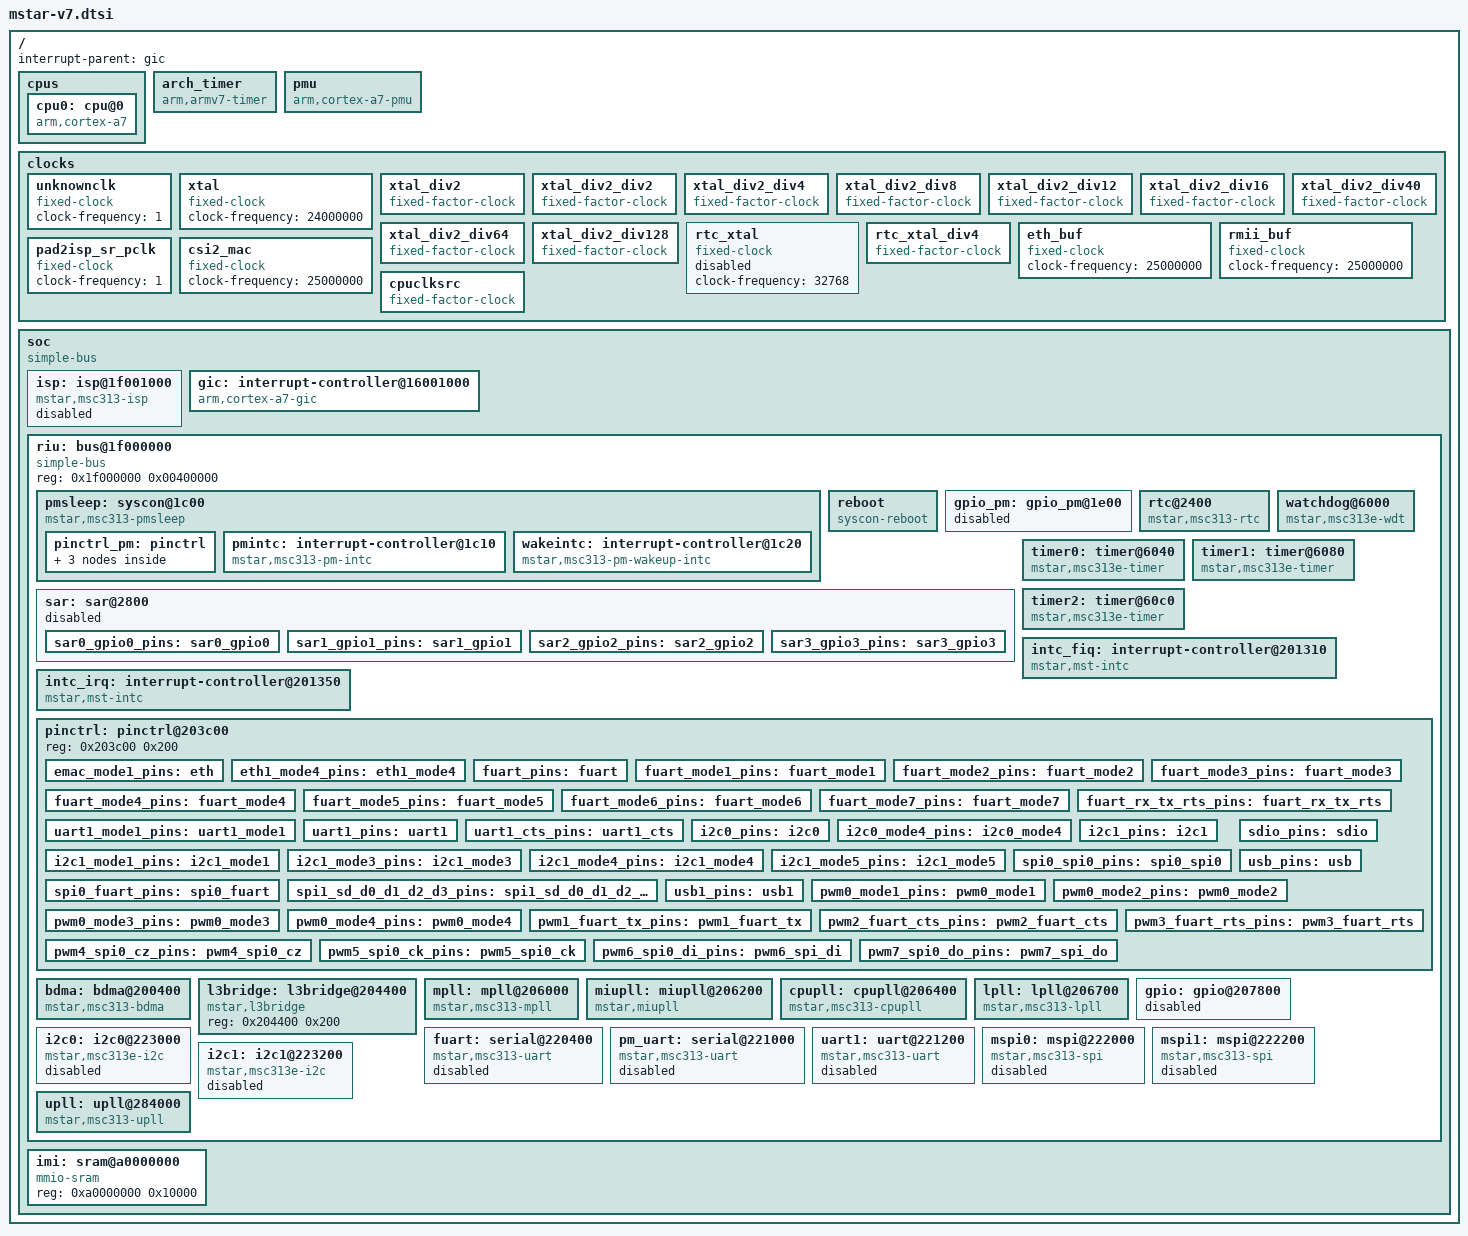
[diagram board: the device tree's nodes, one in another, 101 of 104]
// SPDX-License-Identifier: GPL-2.0-or-later
/*
 * Copyright (c) 2020 thingy.jp.
 * Author: Daniel Palmer <daniel@thingy.jp>
 */

#include <dt-bindings/interrupt-controller/irq.h>
#include <dt-bindings/interrupt-controller/arm-gic.h>
#include <dt-bindings/clock/mstar-msc313-mpll.h>

/ {
	#address-cells = <1>;
	#size-cells = <1>;
	interrupt-parent = <&gic>;

	cpus: cpus {
		#address-cells = <1>;
		#size-cells = <0>;

		cpu0: cpu@0 {
			device_type = "cpu";
			compatible = "arm,cortex-a7";
			reg = <0x0>;
			clocks = <&cpupll>;
			clock-names = "cpuclk";
		};
	};

	arch_timer {
		compatible = "arm,armv7-timer";
		interrupts = <GIC_PPI 13 (GIC_CPU_MASK_SIMPLE(2)
				| IRQ_TYPE_LEVEL_LOW)>,
			     <GIC_PPI 14 (GIC_CPU_MASK_SIMPLE(2)
				| IRQ_TYPE_LEVEL_LOW)>,
			     <GIC_PPI 11 (GIC_CPU_MASK_SIMPLE(2)
				| IRQ_TYPE_LEVEL_LOW)>,
			     <GIC_PPI 10 (GIC_CPU_MASK_SIMPLE(2)
				| IRQ_TYPE_LEVEL_LOW)>;
		/*
		 * we shouldn't need this but the vendor
		 * u-boot is broken
		 */
		clock-frequency = <6000000>;
		arm,cpu-registers-not-fw-configured;
	};

	pmu: pmu {
		compatible = "arm,cortex-a7-pmu";
		interrupts = <GIC_SPI 10 IRQ_TYPE_LEVEL_HIGH>;
/*		interrupts = <GIC_SPI 10 IRQ_TYPE_LEVEL_HIGH>,
			     <GIC_SPI 16 IRQ_TYPE_LEVEL_HIGH>,
			     <GIC_SPI 22 IRQ_TYPE_LEVEL_HIGH>,
			     <GIC_SPI 28 IRQ_TYPE_LEVEL_HIGH>; */
		interrupt-affinity = <&cpu0>;
	};

	clocks: clocks {
		unknownclk: unknownclk {
			#clock-cells = <0>;
			compatible = "fixed-clock";
			clock-frequency = <1>;
		};

		/*
		 * For the msc313e there is only a 24mhz clock input so everything else must come
		 * from this base clock unless there are some on-die oscillators that aren't mentioned
		 * anywhere.
		 */
		xtal: xtal {
			#clock-cells = <0>;
			compatible = "fixed-clock";
			clock-frequency = <24000000>;
		};

		xtal_div2: xtal_div2 {
			#clock-cells = <0>;
			compatible = "fixed-factor-clock";
			clocks = <&xtal>;
			clock-div = <2>;
			clock-mult = <1>;
		};
		
		xtal_div2_div2: xtal_div2_div2 {
			compatible = "fixed-factor-clock";
			#clock-cells = <0>;
			clocks = <&xtal_div2>;
			clock-div = <2>;
			clock-mult = <1>;
		};

		xtal_div2_div4: xtal_div2_div4 {
			compatible = "fixed-factor-clock";
			#clock-cells = <0>;
			clocks = <&xtal_div2>;
			clock-div = <4>;
			clock-mult = <1>;
		};

		xtal_div2_div8: xtal_div2_div8 {
			compatible = "fixed-factor-clock";
			#clock-cells = <0>;
			clocks = <&xtal_div2>;
			clock-div = <8>;
			clock-mult = <1>;
		};

		xtal_div2_div12: xtal_div2_div12 {
			compatible = "fixed-factor-clock";
			#clock-cells = <0>;
			clocks = <&xtal_div2>;
			clock-div = <12>;
			clock-mult = <1>;
		};

		xtal_div2_div16: xtal_div2_div16 {
			compatible = "fixed-factor-clock";
			#clock-cells = <0>;
			clocks = <&xtal_div2>;
			clock-div = <16>;
			clock-mult = <1>;
		};

		xtal_div2_div40: xtal_div2_div40 {
			compatible = "fixed-factor-clock";
			#clock-cells = <0>;
			clocks = <&xtal_div2>;
			clock-div = <40>;
			clock-mult = <1>;
		};

		xtal_div2_div64: xtal_div2_div64 {
			compatible = "fixed-factor-clock";
			#clock-cells = <0>;
			clocks = <&xtal_div2>;
			clock-div = <64>;
			clock-mult = <1>;
		};

		xtal_div2_div128: xtal_div2_div128 {
			compatible = "fixed-factor-clock";
			#clock-cells = <0>;
			clocks = <&xtal_div2>;
			clock-div = <128>;
			clock-mult = <1>;
		};

		rtc_xtal: rtc_xtal {
			#clock-cells = <0>;
			compatible = "fixed-clock";
			clock-frequency = <32768>;
			status = "disabled";
		};

		rtc_xtal_div4: rtc_xtal_div4 {
			compatible = "fixed-factor-clock";
			#clock-cells = <0>;
			clocks = <&rtc_xtal>;
			clock-div = <4>;
			clock-mult = <1>;
		};

		eth_buf: eth_buf {
			#clock-cells = <0>;
			compatible = "fixed-clock";
			clock-frequency = <25000000>;
		};

		rmii_buf: rmii_buf {
			#clock-cells = <0>;
			compatible = "fixed-clock";
			clock-frequency = <25000000>;
		};
		
		pad2isp_sr_pclk: pad2isp_sr_pclk {
			#clock-cells = <0>;
			compatible = "fixed-clock";
			clock-frequency = <1>;
		};
	
		csi2_mac: csi2_mac {
			#clock-cells = <0>;
			compatible = "fixed-clock";
			clock-frequency = <25000000>;
		};

		/*
		 * this is a dummy for now, there must be a switch for the
		 * cpu clk to move between the mpll and the xtal, the spi nor
		 * controller also uses this clock and it works before the
		 * mpll is enabled
		 */
		cpuclksrc: cpuclksrc {
			compatible = "fixed-factor-clock";
			#clock-cells = <0>;
			clocks = <&mpll 1>;
			clock-div = <1>;
			clock-mult = <1>;
		};
	};

	soc: soc {
		compatible = "simple-bus";
		#address-cells = <1>;
		#size-cells = <1>;
		ranges = <0x14000000 0x14000000 0x1000000>,
			 <0x16001000 0x16001000 0x00007000>,
			 <0x1f000000 0x1f000000 0x00400000>,
			 <0xa0000000 0xa0000000 0x20000>;

		isp: isp@1f001000 {
			#address-cells = <1>;
			#size-cells = <0>;
			compatible = "mstar,msc313-isp";
			reg = <0x1f001000 0x400>,
			      <0x1f002c00 0x200>,
			      <0x1f002e00 0x200>,
			      <0x14000000 0x1000000>;
			clock-names = "pm_spi", "cpuclk", "spi";
			clocks = <&pm_muxes MSC313_PM_MUXES_SPI_PM>,
				 <&cpuclksrc>,
				 <&clkgen MSC313_CLKGEN_DEGLITCHES MSC313_CLKGEN_SPI 0>;
			interrupts-extended = <&intc_irq GIC_SPI 5 IRQ_TYPE_LEVEL_HIGH>;
			dmas = <&bdma 0>;
			dma-names = "qspi";
			pinctrl-names = "default";
			pinctrl-0 = <&pm_spi_pins>;
			status = "disabled";
			interconnects = <&miu 0>;
			interconnect-names = "dma-mem";
		};

		gic: interrupt-controller@16001000 {
			compatible = "arm,cortex-a7-gic";
			reg = <0x16001000 0x1000>,
			      <0x16002000 0x2000>,
			      <0x16004000 0x2000>,
			      <0x16006000 0x2000>;
			#interrupt-cells = <3>;
			interrupt-controller;
			interrupts = <GIC_PPI 9 (GIC_CPU_MASK_SIMPLE(2)
					| IRQ_TYPE_LEVEL_LOW)>;
		};

		riu: bus@1f000000 {
			compatible = "simple-bus";
			reg = <0x1f000000 0x00400000>;
			#address-cells = <1>;
			#size-cells = <1>;
			ranges = <0x0 0x1f000000 0x00400000>;

			pmsleep: syscon@1c00 {
				/* msc313e notes
				 *
				 * 1f001c24 -- bit 11 disables pm uart rx
				 * -- bit 15 is set when going into deep sleep
				 *
				 *
				 * 0x1f001cec -- return address after resume
				 * 0x1f001cf0
				 * 0x1f001cf4 -- clk for timers?
				 * 0x1f001cc0 -- ??
				 * 0x1f001cc8  -- set to 9fe8 before deep sleep
				 * 0x1f001ccc  -- set to 9fe8 before deep sleep
				 * 0x1f001cdc  -- set to 0xa5 before deep sleep
				 */
				compatible = "mstar,msc313-pmsleep", "syscon", "simple-mfd";
				reg = <0x1c00 0x100>;
				use-raw-spinlock;

				pinctrl_pm: pinctrl {
					pm_uart_pins: pm_uart {
						function = "pm_uart";
						groups = "pm_uart";
					};
					pm_spi_pins: pm_spi {
						function = "pm_spi";
						groups = "pm_spi";
					};
					pm_irin_pins: pm_irin {
						function = "pm_irin";
						groups = "pm_irin";
					};
				};

				pmintc: interrupt-controller@1c10 {
					compatible = "mstar,msc313-pm-intc";
					interrupt-parent = <&intc_irq>;
					interrupts = <GIC_SPI 2 IRQ_TYPE_LEVEL_HIGH>;
					interrupt-controller;
					#interrupt-cells = <1>;
				};

				wakeintc: interrupt-controller@1c20 {
					compatible = "mstar,msc313-pm-wakeup-intc";
					interrupt-parent = <&intc_irq>;
					interrupts = <GIC_SPI 2 IRQ_TYPE_LEVEL_HIGH>;
					interrupt-controller;
					#interrupt-cells = <2>;
					mstar,pmsleep = <&pmsleep>;
				};
			};

			reboot {
				compatible = "syscon-reboot";
				regmap = <&pmsleep>;
				offset = <0xb8>;
				mask = <0x79>;
			};

			gpio_pm: gpio_pm@1e00 {
				reg = <0x1e00 0x200>;
				#gpio-cells = <2>;
				gpio-controller;
				interrupt-controller;
				#interrupt-cells = <3>;
				interrupt-parent = <&pmintc>;
				status = "disabled";
			};

			rtc@2400 {
				compatible = "mstar,msc313-rtc";
				reg = <0x2400 0x40>;
				clocks = <&xtal_div2>;
				interrupts-extended = <&intc_irq GIC_SPI 44 IRQ_TYPE_LEVEL_HIGH>;
			};

			sar: sar@2800 {
				#gpio-cells = <2>;
				#io-channel-cells = <1>;
				reg = <0x2800 0x200>;
				interrupts-extended = <&intc_irq GIC_SPI 45 IRQ_TYPE_LEVEL_HIGH>,
						      <&wakeintc 1 IRQ_TYPE_LEVEL_HIGH>,
						      <&wakeintc 6 IRQ_TYPE_LEVEL_HIGH>,
						      <&intc_fiq GIC_SPI 24 IRQ_TYPE_LEVEL_HIGH>,
						      <&intc_fiq GIC_SPI 25 IRQ_TYPE_LEVEL_HIGH>,
						      <&intc_fiq GIC_SPI 26 IRQ_TYPE_LEVEL_HIGH>,
						      <&intc_fiq GIC_SPI 27 IRQ_TYPE_LEVEL_HIGH>;
				interrupt-names = "sar",
						  "wakeup",
						  "wakeup_gpio",
						  "sar_gpio0",
						  "sar_gpio1",
						  "sar_gpio2",
						  "sar_gpio3";
				clock-names = "sar_clk";
				clocks = <&pm_muxes MSC313_PM_MUXES_SAR>;
				mstar,pmsleep = <&pmsleep>;
				wakeup-source;
				status = "disabled";
				sar0_gpio0_pins: sar0_gpio0 {
					function = "sar0";
					groups = "sar_gpio0";
				};
				sar1_gpio1_pins: sar1_gpio1 {
					function = "sar1";
					groups = "sar_gpio1";
				};
				sar2_gpio2_pins: sar2_gpio2 {
					function = "sar2";
					groups = "sar_gpio2";
				};
				sar3_gpio3_pins: sar3_gpio3 {
					function = "sar3";
					groups = "sar_gpio3";
				};
			};

			watchdog@6000 {
				compatible = "mstar,msc313e-wdt";
				reg = <0x6000 0x1f>;
				clocks = <&xtal_div2>;
			};

			timer0: timer@6040 {
				compatible = "mstar,msc313e-timer";
				reg = <0x6040 0x40>;
				clocks = <&xtal_div2>;
				interrupts-extended = <&intc_fiq GIC_SPI 0 IRQ_TYPE_LEVEL_HIGH>;
			};

			timer1: timer@6080 {
				compatible = "mstar,msc313e-timer";
				reg = <0x6080 0x40>;
				clocks = <&xtal_div2>;
				interrupts-extended = <&intc_fiq GIC_SPI 1 IRQ_TYPE_LEVEL_HIGH>;
			};

			timer2: timer@60c0 {
				compatible = "mstar,msc313e-timer";
				reg = <0x60c0 0x40>;
				clocks = <&xtal_div2>;
				interrupts-extended = <&intc_fiq GIC_SPI 12 IRQ_TYPE_LEVEL_HIGH>;
			};

			intc_fiq: interrupt-controller@201310 {
				compatible = "mstar,mst-intc";
				reg = <0x201310 0x40>;
				#interrupt-cells = <3>;
				interrupt-controller;
				interrupt-parent = <&gic>;
				mstar,irqs-map-range = <96 127>;
			};

			intc_irq: interrupt-controller@201350 {
				compatible = "mstar,mst-intc";
				reg = <0x201350 0x40>;
				#interrupt-cells = <3>;
				interrupt-controller;
				interrupt-parent = <&gic>;
				mstar,irqs-map-range = <32 95>;
				mstar,intc-no-eoi;
			};

			pinctrl: pinctrl@203c00 {
				reg = <0x203c00 0x200>;
				emac_mode1_pins: eth {
					function = "eth";
					groups = "eth_mode1";
				};
				eth1_mode4_pins: eth1_mode4 {
					function = "eth1";
					groups = "eth1_mode4";
				};
				fuart_pins: fuart {
					function = "fuart";
					groups = "fuart";
				};
				fuart_mode1_pins: fuart_mode1 {
					function = "fuart";
					groups = "fuart_mode1";
				};
				fuart_mode2_pins: fuart_mode2 {
					function = "fuart";
					groups = "fuart_mode2";
				};
				fuart_mode3_pins: fuart_mode3 {
					function = "fuart";
					groups = "fuart_mode3";
				};
				fuart_mode4_pins: fuart_mode4 {
					function = "fuart";
					groups = "fuart_mode4";
				};
				fuart_mode5_pins: fuart_mode5 {
					function = "fuart";
					groups = "fuart_mode5";
				};
				fuart_mode6_pins: fuart_mode6 {
					function = "fuart";
					groups = "fuart_mode6";
				};
				fuart_mode7_pins: fuart_mode7 {
					function = "fuart";
					groups = "fuart_mode7";
				};
				fuart_rx_tx_rts_pins: fuart_rx_tx_rts {
					function = "fuart";
					groups = "fuart_rx_tx_rts";
				};
				uart1_mode1_pins: uart1_mode1 {
					function = "uart1";
					groups = "uart1_mode1";
				};
				uart1_pins: uart1 {
					function = "uart1";
					groups = "fuart_cts_rts";
				};
				uart1_cts_pins: uart1_cts {
					function = "uart1";
					groups = "fuart_cts";
				};
				i2c0_pins: i2c0 {
					function = "i2c0";
					groups = "i2c0";
				};
				i2c0_mode4_pins: i2c0_mode4 {
					function = "i2c0";
					groups = "i2c0_mode4";
				};
				i2c1_pins: i2c1 {
					function = "i2c1";
					groups = "i2c1";
				};
				i2c1_mode1_pins: i2c1_mode1 {
					function = "i2c1";
					groups = "i2c1_mode1";
				};
				i2c1_mode3_pins: i2c1_mode3 {
					function = "i2c1";
					groups = "i2c1_mode3";
				};
				i2c1_mode4_pins: i2c1_mode4 {
					function = "i2c1";
					groups = "i2c1_mode4";
				};
				i2c1_mode5_pins: i2c1_mode5 {
					function = "i2c1";
					groups = "i2c1_mode5";
				};
				spi0_spi0_pins: spi0_spi0 {
					function = "spi0";
					groups = "spi0";
				};
				spi0_fuart_pins: spi0_fuart {
					function = "spi0";
					groups = "fuart";
				};
				spi1_sd_d0_d1_d2_d3_pins: spi1_sd_d0_d1_d2_d3 {
					function = "spi1";
					groups = "sd_d0_d1_d2_d3";
				};
				sdio_pins: sdio {
					function = "sdio";
					groups = "sdio_mode1";
					bias-pull-up;
				};
				usb_pins: usb {
					function = "usb";
					groups = "usb";
				};
				usb1_pins: usb1 {
					function = "usb1";
					groups = "usb1";
				};
				pwm0_mode1_pins: pwm0_mode1 {
					function = "pwm0";
					groups = "pwm0_mode1";
				};
				pwm0_mode2_pins: pwm0_mode2 {
					function = "pwm0";
					groups = "pwm0_mode2";
				};
				pwm0_mode3_pins: pwm0_mode3 {
					function = "pwm0";
					groups = "pwm0_mode3";
				};
				pwm0_mode4_pins: pwm0_mode4 {
					function = "pwm0";
					groups = "pwm0_mode4";
				};
				pwm1_fuart_tx_pins: pwm1_fuart_tx {
					function = "pwm1";
					groups = "fuart_tx";
				};
				pwm2_fuart_cts_pins: pwm2_fuart_cts {
					function = "pwm2";
					groups = "fuart_cts";
				};
				pwm3_fuart_rts_pins: pwm3_fuart_rts {
					function = "pwm3";
					groups = "fuart_rts";
				};
				pwm4_spi0_cz_pins: pwm4_spi0_cz {
					function = "pwm4";
					groups = "spi0_cz";
				};
				pwm5_spi0_ck_pins: pwm5_spi0_ck {
					function = "pwm5";
					groups = "spi0_ck";
				};
				pwm6_spi0_di_pins: pwm6_spi_di {
					function = "pwm6";
					groups = "spi0_di";
				};
				pwm7_spi0_do_pins: pwm7_spi_do {
					function = "pwm7";
					groups = "spi0_do";
				};
			};

			bdma: bdma@200400 {
				compatible = "mstar,msc313-bdma";
				reg = <0x200400 0x80>;
				interrupt-parent = <&intc_irq>;
				interrupts = <GIC_SPI 40 IRQ_TYPE_LEVEL_HIGH>,
					     <GIC_SPI 41 IRQ_TYPE_LEVEL_HIGH>;
				clocks = <&clkgen MSC313_CLKGEN_DEGLITCHES MSC313_CLKGEN_BDMA 0>;
				dma-channels = <2>;
				status = "okay";
				#dma-cells = <1>;
			};

			l3bridge: l3bridge@204400 {
				compatible = "mstar,l3bridge";
				reg = <0x204400 0x200>;
			};

			mpll: mpll@206000 {
				compatible = "mstar,msc313-mpll";
				#clock-cells = <1>;
				reg = <0x206000 0x200>;
				clocks = <&xtal>;
			};

			miupll: miupll@206200 {
				compatible = "mstar,miupll";
				reg = <0x206200 0x200>;
				#clock-cells = <0>;
				clocks = <&xtal>;
			};

			cpupll: cpupll@206400 {
				compatible = "mstar,msc313-cpupll";
				reg = <0x206400 0x200>;
				#clock-cells = <0>;
				clocks = <&clkgen_pll MSTAR_MPLL_GATE_MPLL_432>;
			};

			lpll: lpll@206700 {
				compatible = "mstar,msc313-lpll";
				reg = <0x206700 0x100>;
				#clock-cells = <1>;
				clocks = <&mpll MSTAR_MSC313_MPLL_DIV2>;
			};

			gpio: gpio@207800 {
				#gpio-cells = <2>;
				reg = <0x207800 0x200>;
				gpio-controller;
				#interrupt-cells = <2>;
				interrupt-controller;
				interrupt-parent = <&intc_fiq>;
				status = "disabled";
			};

			fuart: serial@220400 {
				compatible = "mstar,msc313-uart";
				reg = <0x220400 0x100>;
				/*
				 * DMA registers
				 * <0x1f220600 0x100>
				 */
				interrupt-parent = <&intc_irq>;
				interrupts = <GIC_SPI 47 IRQ_TYPE_LEVEL_HIGH>;
				reg-shift = <3>;
				clocks = <&clkgen MSC313_CLKGEN_DEGLITCHES MSC313_CLKGEN_FUART 0>;
				pinctrl-names = "default";
				pinctrl-0 = <&fuart_pins>;
				status = "disabled";
			};

			pm_uart: serial@221000 {
				compatible = "mstar,msc313-uart", "snps,dw-apb-uart";
				reg = <0x221000 0x100>;
				reg-shift = <3>;
				interrupts-extended = <&intc_irq GIC_SPI 34 IRQ_TYPE_LEVEL_HIGH>;
				clocks = <&clkgen MSC313_CLKGEN_DEGLITCHES MSC313_CLKGEN_UART0 0>;
				pinctrl-names = "default";
				pinctrl-0 = <&pm_uart_pins>;
				status = "disabled";
			};

			uart1: uart@221200 {
				compatible = "mstar,msc313-uart", "snps,dw-apb-uart";
				reg = <0x221200 0x100>;
				reg-shift = <3>;
				interrupts-extended = <&intc_irq GIC_SPI 35 IRQ_TYPE_LEVEL_HIGH>;
				clocks = <&clkgen MSC313_CLKGEN_DEGLITCHES MSC313_CLKGEN_UART1 0>;
				status = "disabled";
			};

			mspi0: mspi@222000 {
				compatible = "mstar,msc313-spi";
				reg = <0x222000 0x200>;
				interrupt-parent = <&intc_irq>;
				interrupts = <GIC_SPI 38 IRQ_TYPE_LEVEL_HIGH>;
				clocks = <&clkgen MSC313_CLKGEN_DEGLITCHES MSC313_CLKGEN_MSPI0 0>;
				status = "disabled";
			};

			mspi1: mspi@222200 {
				compatible = "mstar,msc313-spi";
				reg = <0x222200 0x200>;
				interrupt-parent = <&intc_irq>;
				interrupts = <GIC_SPI 39 IRQ_TYPE_LEVEL_HIGH>;
				clocks = <&clkgen MSC313_CLKGEN_DEGLITCHES MSC313_CLKGEN_MSPI1 0>;
				status = "disabled";
			};

			i2c0: i2c0@223000 {
				compatible = "mstar,msc313e-i2c";
				reg = <0x223000 0x200>;
				interrupts-extended = <&intc_irq GIC_SPI 36 IRQ_TYPE_LEVEL_HIGH>;
				#address-cells = <1>;
				#size-cells = <0>;
				clock-names = "i2c_clk";
				clocks = <&clkgen MSC313_CLKGEN_DEGLITCHES MSC313_CLKGEN_MIIC0 0>;
				pinctrl-names = "default";
				pinctrl-0 = <&i2c0_pins>;
				interconnect-names = "dma-mem";
				interconnects = <&miu 0>;
				status = "disabled";
			};

			i2c1: i2c1@223200 {
				compatible = "mstar,msc313e-i2c";
				reg = <0x223200 0x200>;
				interrupts-extended = <&intc_irq GIC_SPI 37 IRQ_TYPE_LEVEL_HIGH>;
				#address-cells = <1>;
				#size-cells = <0>;
				clock-names = "i2c_clk";
				clocks = <&clkgen MSC313_CLKGEN_DEGLITCHES MSC313_CLKGEN_MIIC1 0>;
				pinctrl-names = "default";
				pinctrl-0 = <&i2c1_pins>;
				interconnect-names = "dma-mem";
				interconnects = <&miu 0>;
				status = "disabled";
			};

			upll: upll@284000 {
				#clock-cells = <1>;
				compatible = "mstar,msc313-upll";
				reg = <0x284000 0x20>;
				clocks = <&xtal>;
			};
		};

		imi: sram@a0000000 {
			compatible = "mmio-sram";
			reg = <0xa0000000 0x10000>;
		};
	};
};
